# LPC15xx register map
File version: 0.7
CPU: CM3 r2p1, little endian, no MPU, no FPU, 3 interrupt priority bits
Registers are 32-bit, read-write, reset 0x0 unless marked. A register's access mark holds for its fields unless they carry their own. Offsets are from the block's base; [hi:lo] are bit positions; {n}, {i} and the like mark numbered series.

## SCTIPU — SCT Input Processing Unit (IPU)
Base 0x400B8000
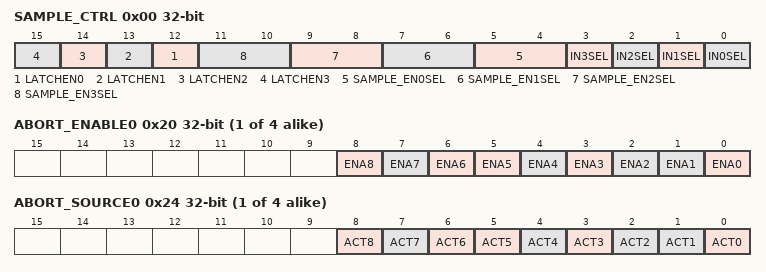
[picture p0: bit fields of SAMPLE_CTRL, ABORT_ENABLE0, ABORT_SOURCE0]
0x00 SAMPLE_CTRL — SCT IPU sample control register. Contains the input mux selects, latch/sample-enable mux selects, and sample overrride bits for the SAMPLE module.
  [n+12] LATCHEN{n} (n=0..3) — Enable latch for output channel {n}.
    0=TRANSPARENT_MODE_SA (Transparent mode. Sample_Output({n}) latch is forced into transparent mode. The selected Sample_Input is passed directly through to Sample_Output({n}). The sample-enable control line selected for this latch has no effect.); 1=LATCHED_MODE_THE_SA (Latched mode. The Sample_Output({n}) latch is operational and will sample or latch based on the state of the selected sample-enable control signal.)
  [2n+5:2n+4] SAMPLE_EN{n}SEL (n=0..3) — Select the sample enable input as the latch/sample-enable control for the Sample_Output({n}) latch. Depending on the value of the corresponding LATCHn_EN bit, this latch is transparent when the LATCHn_EN bit is 1 or latched when the LATCHn_EN bit is 0.
    0=SELECTS_SAMPLE_ENABL (Selects Sample_Enable_A as the latch/sample-enable control for the Sample_Output({n}) latch.); 1=SELECTS_SAMPLE_ENABL (Selects Sample_Enable_B as the latch/sample-enable control for the Sample_Output({n}) latch.); 2=SELECTS_SAMPLE_ENABL (Selects Sample_Enable_C as the latch/sample-enable control for the Sample_Output({n}) latch.); 3=SELECTS_SAMPLE_ENABL (Selects Sample_Enable_D as the latch/sample-enable control for the Sample_Output({n}) latch.)
  [3] IN3SEL — Select. SCT IPU input source for output channel 3.
    0=SAMPE_IN_A3_SELECT_ (SAMPE_IN_A3. Select input SAMPLE_IN_A3.); 1=SAMPE_IN_B3_SELECT_ (SAMPE_IN_B3. Select input SAMPLE_IN_B3.)
  [2] IN2SEL — Select SCT IPU input source for output channel 2.
    0=SAMPE_IN_A2_SELECT_ (SAMPE_IN_A2. Select input SAMPLE_IN_A2.); 1=SAMPE_IN_B2_SELECT_ (SAMPE_IN_B2. Select input SAMPLE_IN_B2.)
  [1] IN1SEL — Select SCT IPU input source for output channel 1.
    0=SAMPE_IN_A1_SELECT_ (SAMPE_IN_A1. Select input SAMPLE_IN_A1.); 1=SAMPE_IN_B1_SELECT_ (SAMPE_IN_B1. Select input SAMPLE_IN_B1.)
  [0] IN0SEL — Select SCT IPU input source for output channel 0.
    0=SAMPE_IN_A0_SELECT_ (SAMPE_IN_A0. Select input SAMPLE_IN_A0.); 1=SAMPE_IN_B0_SELECT_ (SAMPE_IN_B0. Select input SAMPLE_IN_B0.)
{0x20+0x20*i} ABORT_ENABLE{i} (i=0..3) — SCT IPU abort enable register: Selects which input source contributes to ORed Abort Output 0.
  [all] fields
    0=DISABLED_; 1=ENABLED_
  [8] ENA8 — Enable abort source ADC1_THCMP_IRQ.
  [7] ENA7 — Enable abort source ADC0_THCMP_IRQ.
  [6] ENA6 — Enable abort source SCT0_OUT9.
  [n] ENA{n} (n=2..5) — Enable abort source ACMP{n-2} output.
  [1] ENA1 — Enable abort source SCT_ABORT1.
  [0] ENA0 — Enable abort source SCT_ABORT0.
{0x24+0x20*i} ABORT_SOURCE{i} (i=0..3) — SCT IPU abort source register: Status register indicating which input source caused abort output 0.
  [all] fields
    0=NOT_ACTIVATED_; 1=ACTIVATED_
  [8] ACT8 — Source ADC1_THCMP_IRQ activated. This bit is set by hardware when the source is actived. Write 0 to clear.
  [7] ACT7 — Source ADC0_THCMP_IRQ activated. This bit is set by hardware when the source is actived. Write 0 to clear.
  [6] ACT6 — Source SCT0_OUT9 activated. This bit is set by hardware when the source is actived. Write 0 to clear.
  [n] ACT{n} (n=2..5) — Source ACMP{n-2} output activated. This bit is set by hardware when the source is actived. Write 0 to clear.
  [1] ACT1 — Source SCT_ABORT1 activated. This bit is set by hardware when the source is actived. Write 0 to clear. This function can be assigned to any pin via the PINASSIGN10 register in the switch matrix.
  [0] ACT0 — Source SCT_ABORT0 activated. This bit is set by hardware when the source is actived. Write 0 to clear. This function can be assigned to any pin via the PINASSIGN10 register in the switch matrix.
